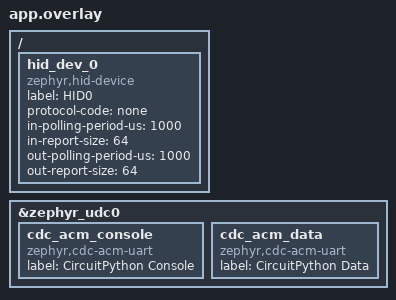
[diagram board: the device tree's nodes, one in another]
&zephyr_udc0 {
	cdc_acm_console: cdc_acm_console {
		compatible = "zephyr,cdc-acm-uart";
		label = "CircuitPython Console";
	};
	cdc_acm_data: cdc_acm_data {
		compatible = "zephyr,cdc-acm-uart";
		label = "CircuitPython Data";
	};
};

/ {
	hid_dev_0: hid_dev_0 {
		compatible = "zephyr,hid-device";
		label = "HID0";
		protocol-code = "none";
		in-polling-period-us = <1000>;
		in-report-size = <64>;
		out-polling-period-us = <1000>;
		out-report-size = <64>;
	};
};
